AUTOSAR XML
package /BbwComponents
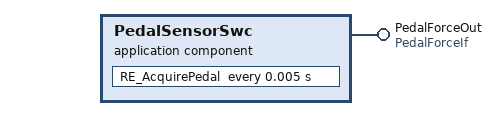
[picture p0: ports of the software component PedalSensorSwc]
  application sw component type PedalSensorSwc
    provide port PedalForceOut: provided-interface=PedalForceIf
    behavior PedalSensor_IB
      runnable RE_AcquirePedal: execution-time-wcet=0.0010
      timing event TE_Pedal_5ms: start-on-event=RE_AcquirePedal, period=0.005
